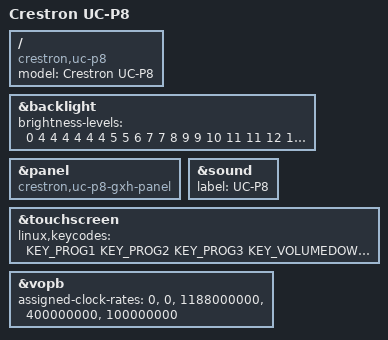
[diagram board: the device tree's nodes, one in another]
// SPDX-License-Identifier: (GPL-2.0+ OR MIT)
/*
 * Crestron UC-P8 room phone: 800x1280 MIPI-DSI panel with an ILI9881C
 * controller ("gxh" in the stock firmware).
 *
 * NOT TESTED ON HARDWARE. This file comes from the stock UC-P10/P8 device
 * tree and from the UC-P10 board file. The UC-P8 and the UC-P10 share the
 * stock firmware and its device tree. The only differences in that tree
 * are the panel (selected by the LCD ID), the backlight table and the
 * order of the touch keys. The panel rotation and the touch coordinates
 * are the UC-P10 values and are not checked on a UC-P8.
 */

/dts-v1/;

#include "rk3399-crestron-uc-pxx.dtsi"

/ {
	model = "Crestron UC-P8";
	compatible = "crestron,uc-p8", "rockchip,rk3399";
};

&backlight {
	/*
	 * The stock "brightness-levels" table for the units that are not a
	 * UC-P10. The highest duty cycle is 168/255.
	 */
	brightness-levels = <
		  0   4   4   4   4   4   4   5
		  5   6   7   7   8   9   9  10
		 11  11  12  13  13  14  15  15
		 16  17  17  18  19  19  20  21
		 21  22  23  23  24  25  25  26
		 27  27  28  29  29  30  31  31
		 32  33  33  34  35  35  36  37
		 37  38  39  39  40  41  41  42
		 43  43  44  45  45  46  47  47
		 48  49  49  50  51  51  52  53
		 53  54  55  55  56  57  57  58
		 59  59  60  61  61  62  63  63
		 64  65  65  66  67  67  68  69
		 69  70  71  71  72  73  73  74
		 75  75  76  77  77  78  79  79
		 80  81  81  82  83  83  84  85
		 85  86  87  87  88  89  89  90
		 91  91  92  93  93  94  95  95
		 96  97  97  98  99  99 100 101
		101 102 103 103 104 105 105 106
		107 107 108 109 109 110 111 111
		112 113 113 114 115 115 116 117
		117 118 119 119 120 121 121 122
		123 123 124 125 125 126 127 127
		128 129 129 130 131 131 132 133
		133 134 135 135 136 137 137 138
		139 139 140 141 141 142 143 143
		144 145 145 146 147 147 148 149
		149 150 151 151 152 153 153 154
		155 155 156 157 157 158 159 159
		160 160 161 161 162 162 163 163
		164 164 165 165 166 166 167 168>;
};

&panel {
	compatible = "crestron,uc-p8-gxh-panel", "ilitek,ili9881c";
};

&sound {
	label = "UC-P8";
};

&touchscreen {
	/* T15 key order: the stock "linux,gpio-keymap" (not the _p10 map) */
	linux,keycodes = <KEY_PROG1 KEY_PROG2 KEY_PROG3
			  KEY_VOLUMEDOWN KEY_VOLUMEUP KEY_MUTE>;
};

&vopb {
	/*
	 * VPLL at 1188 MHz, so that the integer divider gives exactly the
	 * 66 MHz pixel clock of the panel (VPLL/18).
	 */
	assigned-clock-rates = <0>, <0>,
			       <1188000000>, <400000000>, <100000000>;
};
